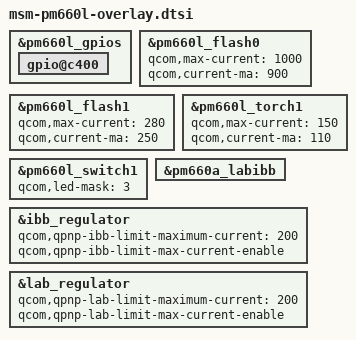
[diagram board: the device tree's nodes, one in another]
/* Copyright (c) 2016-2017, The Linux Foundation. All rights reserved.
 *
 * This program is free software; you can redistribute it and/or modify
 * it under the terms of the GNU General Public License version 2 and
 * only version 2 as published by the Free Software Foundation.
 *
 * This program is distributed in the hope that it will be useful,
 * but WITHOUT ANY WARRANTY; without even the implied warranty of
 * MERCHANTABILITY or FITNESS FOR A PARTICULAR PURPOSE.  See the
 * GNU General Public License for more details.
 */

&pm660l_gpios {
	gpio@c400 {
		status = "ok";
	};
};

&pm660l_flash0 {
	qcom,max-current = <1000>;
	qcom,current-ma = <900>;
};

&pm660l_flash1 {
	qcom,max-current = <280>;
	qcom,current-ma = <250>;
};

&pm660l_torch1 {
	qcom,max-current = <150>;
	qcom,current-ma = <110>;
};

&pm660l_switch1 {
	qcom,led-mask = <3>;
};

&pm660a_labibb {
	status = "okay";
};

&ibb_regulator {
	qcom,qpnp-ibb-limit-maximum-current = <200>;
	qcom,qpnp-ibb-limit-max-current-enable;
};

&lab_regulator {
	qcom,qpnp-lab-limit-maximum-current = <200>;
	qcom,qpnp-lab-limit-max-current-enable;
};
